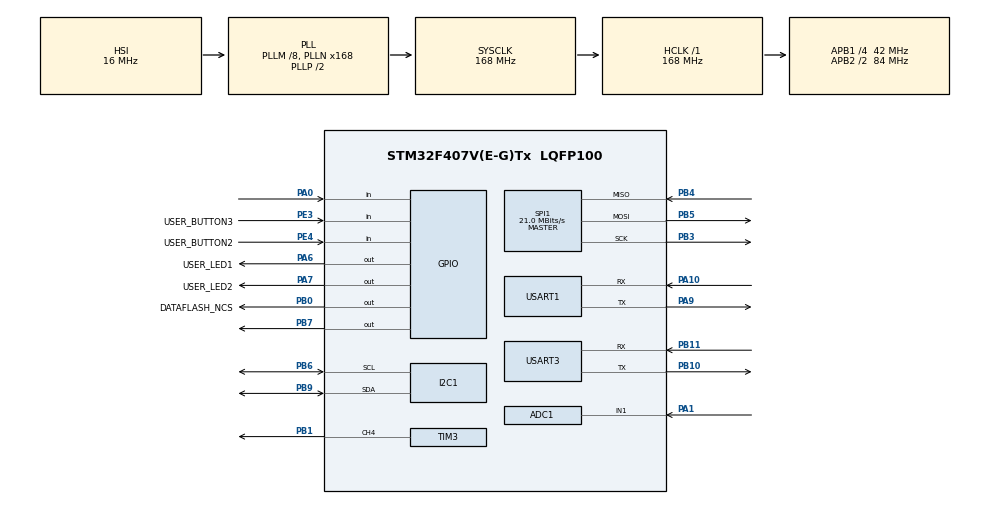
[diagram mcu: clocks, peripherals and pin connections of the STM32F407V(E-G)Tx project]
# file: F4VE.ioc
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ADC1.Channel-0\#ChannelRegularConversion=ADC_CHANNEL_1
ADC1.NbrOfConversionFlag=1
ADC1.Rank-0\#ChannelRegularConversion=1
ADC1.SamplingTime-0\#ChannelRegularConversion=ADC_SAMPLETIME_3CYCLES
ADC1.master=1
Mcu.Family=STM32F4
Mcu.Name=STM32F407V(E-G)Tx
Mcu.Package=LQFP100
NVIC.PriorityGroup=NVIC_PRIORITYGROUP_4
NVIC.SPI1_IRQn=true\:0\:0\:false\:false\:true\:true\:true\:true
PA0-WKUP.Signal=GPIO_Input
PA1.Signal=ADCx_IN1
PA10.Mode=Asynchronous
PA10.Signal=USART1_RX
PA6.GPIO_Label=USER_LED1
PA6.Signal=GPIO_Output
PA7.GPIO_Label=USER_LED2
PA7.Signal=GPIO_Output
PA9.Mode=Asynchronous
PA9.Signal=USART1_TX
PB0.GPIO_Label=DATAFLASH_NCS
PB0.Signal=GPIO_Output
PB1.Signal=S_TIM3_CH4
PB10.Mode=Asynchronous
PB10.Signal=USART3_TX
PB11.Mode=Asynchronous
PB11.Signal=USART3_RX
PB3.GPIO_Speed=GPIO_SPEED_FREQ_LOW
PB3.Mode=Full_Duplex_Master
PB3.Signal=SPI1_SCK
PB4.GPIO_Speed=GPIO_SPEED_FREQ_LOW
PB4.Mode=Full_Duplex_Master
PB4.Signal=SPI1_MISO
PB5.GPIO_Speed=GPIO_SPEED_FREQ_LOW
PB5.Mode=Full_Duplex_Master
PB5.Signal=SPI1_MOSI
PB6.Mode=I2C
PB6.Signal=I2C1_SCL
PB7.Signal=GPIO_Output
PB9.Mode=I2C
PB9.Signal=I2C1_SDA
PE3.GPIO_Label=USER_BUTTON3
PE3.GPIO_PuPd=GPIO_PULLUP
PE3.Signal=GPIO_Input
PE4.GPIO_Label=USER_BUTTON2
PE4.GPIO_PuPd=GPIO_PULLUP
PE4.Signal=GPIO_Input
ProjectManager.HeapSize=0x200
ProjectManager.StackSize=0x400
ProjectManager.TargetToolchain=STM32CubeIDE
RCC.48MHZClocksFreq_Value=84000000
RCC.AHBFreq_Value=168000000
RCC.APB1CLKDivider=RCC_HCLK_DIV4
RCC.APB1Freq_Value=42000000
RCC.APB1TimFreq_Value=84000000
RCC.APB2CLKDivider=RCC_HCLK_DIV2
RCC.APB2Freq_Value=84000000
RCC.APB2TimFreq_Value=168000000
RCC.CortexFreq_Value=168000000
RCC.HCLKFreq_Value=168000000
RCC.HSE_VALUE=25000000
RCC.HSI_VALUE=16000000
RCC.LSE_VALUE=32768
RCC.PLLM=8
RCC.PLLN=168
RCC.SYSCLKFreq_VALUE=168000000
RCC.SYSCLKSource=RCC_SYSCLKSOURCE_PLLCLK
RCC.VCOOutputFreq_Value=336000000
SH.ADCx_IN1.0=ADC1_IN1,IN1
SH.S_TIM3_CH4.0=TIM3_CH4,PWM Generation4 CH4
SPI1.BaudRatePrescaler=SPI_BAUDRATEPRESCALER_4
SPI1.CalculateBaudRate=21.0 MBits/s
SPI1.Direction=SPI_DIRECTION_2LINES
SPI1.Mode=SPI_MODE_MASTER
SPI1.VirtualType=VM_MASTER
TIM3.Channel-PWM\ Generation4\ CH4=TIM_CHANNEL_4
USART1.VirtualMode=VM_ASYNC
USART3.VirtualMode=VM_ASYNC
VP_RTC_VS_RTC_Activate.Mode=RTC_Enabled
VP_RTC_VS_RTC_Calendar.Mode=RTC_Calendar
board=custom

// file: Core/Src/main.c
/* USER CODE BEGIN Header */
/**
  ******************************************************************************
  * @file           : main.c
  * @brief          : Main program body
  ******************************************************************************
  * @attention
  *
  * Copyright (c) 2024 STMicroelectronics.
  * All rights reserved.
  *
  * This software is licensed under terms that can be found in the LICENSE file
  * in the root directory of this software component.
  * If no LICENSE file comes with this software, it is provided AS-IS.
  *
  ******************************************************************************
  */
/* USER CODE END Header */
#include "main.h"

ADC_HandleTypeDef hadc1;

I2C_HandleTypeDef hi2c1;

RTC_HandleTypeDef hrtc;

SPI_HandleTypeDef hspi1;

TIM_HandleTypeDef htim3;

UART_HandleTypeDef huart1;
UART_HandleTypeDef huart3;

void SystemClock_Config(void);
static void MX_GPIO_Init(void);
static void MX_SPI1_Init(void);
static void MX_USART1_UART_Init(void);
static void MX_RTC_Init(void);
static void MX_USART3_UART_Init(void);
static void MX_TIM3_Init(void);
static void MX_ADC1_Init(void);
static void MX_I2C1_Init(void);

int main(void)
{

  /* MCU Configuration--------------------------------------------------------*/

  /* Reset of all peripherals, Initializes the Flash interface and the Systick. */
  HAL_Init();

  /* Configure the system clock */
  SystemClock_Config();

  /* Initialize all configured peripherals */
  MX_GPIO_Init();
  MX_SPI1_Init();
  MX_USART1_UART_Init();
  MX_RTC_Init();
  MX_USART3_UART_Init();
  MX_TIM3_Init();
  MX_ADC1_Init();
  MX_I2C1_Init();
  /* USER CODE BEGIN 2 */
  app();
  /* USER CODE END 2 */

  /* Infinite loop */
  while (1)
  {

  }
}

void SystemClock_Config(void)
{
  RCC_OscInitTypeDef RCC_OscInitStruct = {0};
  RCC_ClkInitTypeDef RCC_ClkInitStruct = {0};

  /** Configure the main internal regulator output voltage
  */
  __HAL_RCC_PWR_CLK_ENABLE();
  __HAL_PWR_VOLTAGESCALING_CONFIG(PWR_REGULATOR_VOLTAGE_SCALE1);

  /** Initializes the RCC Oscillators according to the specified parameters
  * in the RCC_OscInitTypeDef structure.
  */
  RCC_OscInitStruct.OscillatorType = RCC_OSCILLATORTYPE_HSI|RCC_OSCILLATORTYPE_LSI;
  RCC_OscInitStruct.HSIState = RCC_HSI_ON;
  RCC_OscInitStruct.HSICalibrationValue = RCC_HSICALIBRATION_DEFAULT;
  RCC_OscInitStruct.LSIState = RCC_LSI_ON;
  RCC_OscInitStruct.PLL.PLLState = RCC_PLL_ON;
  RCC_OscInitStruct.PLL.PLLSource = RCC_PLLSOURCE_HSI;
  RCC_OscInitStruct.PLL.PLLM = 8;
  RCC_OscInitStruct.PLL.PLLN = 168;
  RCC_OscInitStruct.PLL.PLLP = RCC_PLLP_DIV2;
  RCC_OscInitStruct.PLL.PLLQ = 4;
  if (HAL_RCC_OscConfig(&RCC_OscInitStruct) != HAL_OK)
  {
    Error_Handler();
  }

  /** Initializes the CPU, AHB and APB buses clocks
  */
  RCC_ClkInitStruct.ClockType = RCC_CLOCKTYPE_HCLK|RCC_CLOCKTYPE_SYSCLK
                              |RCC_CLOCKTYPE_PCLK1|RCC_CLOCKTYPE_PCLK2;
  RCC_ClkInitStruct.SYSCLKSource = RCC_SYSCLKSOURCE_PLLCLK;
  RCC_ClkInitStruct.AHBCLKDivider = RCC_SYSCLK_DIV1;
  RCC_ClkInitStruct.APB1CLKDivider = RCC_HCLK_DIV4;
  RCC_ClkInitStruct.APB2CLKDivider = RCC_HCLK_DIV2;

  if (HAL_RCC_ClockConfig(&RCC_ClkInitStruct, FLASH_LATENCY_5) != HAL_OK)
  {
    Error_Handler();
  }
}

static void MX_ADC1_Init(void)
{

  ADC_ChannelConfTypeDef sConfig = {0};

  /** Configure the global features of the ADC (Clock, Resolution, Data Alignment and number of conversion)
  */
  hadc1.Instance = ADC1;
  hadc1.Init.ClockPrescaler = ADC_CLOCK_SYNC_PCLK_DIV4;
  hadc1.Init.Resolution = ADC_RESOLUTION_12B;
  hadc1.Init.ScanConvMode = DISABLE;
  hadc1.Init.ContinuousConvMode = DISABLE;
  hadc1.Init.DiscontinuousConvMode = DISABLE;
  hadc1.Init.ExternalTrigConvEdge = ADC_EXTERNALTRIGCONVEDGE_NONE;
  hadc1.Init.ExternalTrigConv = ADC_SOFTWARE_START;
  hadc1.Init.DataAlign = ADC_DATAALIGN_RIGHT;
  hadc1.Init.NbrOfConversion = 1;
  hadc1.Init.DMAContinuousRequests = DISABLE;
  hadc1.Init.EOCSelection = ADC_EOC_SINGLE_CONV;
  if (HAL_ADC_Init(&hadc1) != HAL_OK)
  {
    Error_Handler();
  }

  /** Configure for the selected ADC regular channel its corresponding rank in the sequencer and its sample time.
  */
  sConfig.Channel = ADC_CHANNEL_1;
  sConfig.Rank = 1;
  sConfig.SamplingTime = ADC_SAMPLETIME_3CYCLES;
  if (HAL_ADC_ConfigChannel(&hadc1, &sConfig) != HAL_OK)
  {
    Error_Handler();
  }

}

static void MX_I2C1_Init(void)
{

  hi2c1.Instance = I2C1;
  hi2c1.Init.ClockSpeed = 100000;
  hi2c1.Init.DutyCycle = I2C_DUTYCYCLE_2;
  hi2c1.Init.OwnAddress1 = 0;
  hi2c1.Init.AddressingMode = I2C_ADDRESSINGMODE_7BIT;
  hi2c1.Init.DualAddressMode = I2C_DUALADDRESS_DISABLE;
  hi2c1.Init.OwnAddress2 = 0;
  hi2c1.Init.GeneralCallMode = I2C_GENERALCALL_DISABLE;
  hi2c1.Init.NoStretchMode = I2C_NOSTRETCH_DISABLE;
  if (HAL_I2C_Init(&hi2c1) != HAL_OK)
  {
    Error_Handler();
  }

}

static void MX_RTC_Init(void)
{

  RTC_TimeTypeDef sTime = {0};
  RTC_DateTypeDef sDate = {0};

  /** Initialize RTC Only
  */
  hrtc.Instance = RTC;
  hrtc.Init.HourFormat = RTC_HOURFORMAT_24;
  hrtc.Init.AsynchPrediv = 127;
  hrtc.Init.SynchPrediv = 255;
  hrtc.Init.OutPut = RTC_OUTPUT_DISABLE;
  hrtc.Init.OutPutPolarity = RTC_OUTPUT_POLARITY_HIGH;
  hrtc.Init.OutPutType = RTC_OUTPUT_TYPE_OPENDRAIN;
  if (HAL_RTC_Init(&hrtc) != HAL_OK)
  {
    Error_Handler();
  }

  /** Initialize RTC and set the Time and Date
  */
  sTime.Hours = 0x0;
  sTime.Minutes = 0x0;
  sTime.Seconds = 0x0;
  sTime.DayLightSaving = RTC_DAYLIGHTSAVING_NONE;
  sTime.StoreOperation = RTC_STOREOPERATION_RESET;
  if (HAL_RTC_SetTime(&hrtc, &sTime, RTC_FORMAT_BCD) != HAL_OK)
  {
    Error_Handler();
  }
  sDate.WeekDay = RTC_WEEKDAY_MONDAY;
  sDate.Month = RTC_MONTH_JANUARY;
  sDate.Date = 0x1;
  sDate.Year = 0x0;

  if (HAL_RTC_SetDate(&hrtc, &sDate, RTC_FORMAT_BCD) != HAL_OK)
  {
    Error_Handler();
  }

}

static void MX_SPI1_Init(void)
{

  /* SPI1 parameter configuration*/
  hspi1.Instance = SPI1;
  hspi1.Init.Mode = SPI_MODE_MASTER;
  hspi1.Init.Direction = SPI_DIRECTION_2LINES;
  hspi1.Init.DataSize = SPI_DATASIZE_8BIT;
  hspi1.Init.CLKPolarity = SPI_POLARITY_LOW;
  hspi1.Init.CLKPhase = SPI_PHASE_1EDGE;
  hspi1.Init.NSS = SPI_NSS_SOFT;
  hspi1.Init.BaudRatePrescaler = SPI_BAUDRATEPRESCALER_4;
  hspi1.Init.FirstBit = SPI_FIRSTBIT_MSB;
  hspi1.Init.TIMode = SPI_TIMODE_DISABLE;
  hspi1.Init.CRCCalculation = SPI_CRCCALCULATION_DISABLE;
  hspi1.Init.CRCPolynomial = 10;
  if (HAL_SPI_Init(&hspi1) != HAL_OK)
  {
    Error_Handler();
  }

}

static void MX_TIM3_Init(void)
{

  TIM_MasterConfigTypeDef sMasterConfig = {0};
  TIM_OC_InitTypeDef sConfigOC = {0};

  htim3.Instance = TIM3;
  htim3.Init.Prescaler = 0;
  htim3.Init.CounterMode = TIM_COUNTERMODE_UP;
  htim3.Init.Period = 65535;
  htim3.Init.ClockDivision = TIM_CLOCKDIVISION_DIV1;
  htim3.Init.AutoReloadPreload = TIM_AUTORELOAD_PRELOAD_DISABLE;
  if (HAL_TIM_PWM_Init(&htim3) != HAL_OK)
  {
    Error_Handler();
  }
  sMasterConfig.MasterOutputTrigger = TIM_TRGO_RESET;
  sMasterConfig.MasterSlaveMode = TIM_MASTERSLAVEMODE_DISABLE;
  if (HAL_TIMEx_MasterConfigSynchronization(&htim3, &sMasterConfig) != HAL_OK)
  {
    Error_Handler();
  }
  sConfigOC.OCMode = TIM_OCMODE_PWM1;
  sConfigOC.Pulse = 0;
  sConfigOC.OCPolarity = TIM_OCPOLARITY_HIGH;
  sConfigOC.OCFastMode = TIM_OCFAST_DISABLE;
  if (HAL_TIM_PWM_ConfigChannel(&htim3, &sConfigOC, TIM_CHANNEL_4) != HAL_OK)
  {
    Error_Handler();
  }
  HAL_TIM_MspPostInit(&htim3);

}

static void MX_USART1_UART_Init(void)
{

  huart1.Instance = USART1;
  huart1.Init.BaudRate = 115200;
  huart1.Init.WordLength = UART_WORDLENGTH_8B;
  huart1.Init.StopBits = UART_STOPBITS_1;
  huart1.Init.Parity = UART_PARITY_NONE;
  huart1.Init.Mode = UART_MODE_TX_RX;
  huart1.Init.HwFlowCtl = UART_HWCONTROL_NONE;
  huart1.Init.OverSampling = UART_OVERSAMPLING_16;
  if (HAL_UART_Init(&huart1) != HAL_OK)
  {
    Error_Handler();
  }

}

static void MX_USART3_UART_Init(void)
{

  huart3.Instance = USART3;
  huart3.Init.BaudRate = 115200;
  huart3.Init.WordLength = UART_WORDLENGTH_8B;
  huart3.Init.StopBits = UART_STOPBITS_1;
  huart3.Init.Parity = UART_PARITY_NONE;
  huart3.Init.Mode = UART_MODE_TX_RX;
  huart3.Init.HwFlowCtl = UART_HWCONTROL_NONE;
  huart3.Init.OverSampling = UART_OVERSAMPLING_16;
  if (HAL_UART_Init(&huart3) != HAL_OK)
  {
    Error_Handler();
  }

}

static void MX_GPIO_Init(void)
{
  GPIO_InitTypeDef GPIO_InitStruct = {0};

  /* GPIO Ports Clock Enable */
  __HAL_RCC_GPIOE_CLK_ENABLE();
  __HAL_RCC_GPIOA_CLK_ENABLE();
  __HAL_RCC_GPIOB_CLK_ENABLE();

  /*Configure GPIO pin Output Level */
  HAL_GPIO_WritePin(GPIOA, USER_LED1_Pin|USER_LED2_Pin, GPIO_PIN_RESET);

  /*Configure GPIO pin Output Level */
  HAL_GPIO_WritePin(GPIOB, DATAFLASH_NCS_Pin|GPIO_PIN_7, GPIO_PIN_RESET);

  /*Configure GPIO pins : USER_BUTTON3_Pin USER_BUTTON2_Pin */
  GPIO_InitStruct.Pin = USER_BUTTON3_Pin|USER_BUTTON2_Pin;
  GPIO_InitStruct.Mode = GPIO_MODE_INPUT;
  GPIO_InitStruct.Pull = GPIO_PULLUP;
  HAL_GPIO_Init(GPIOE, &GPIO_InitStruct);

  /*Configure GPIO pin : PA0 */
  GPIO_InitStruct.Pin = GPIO_PIN_0;
  GPIO_InitStruct.Mode = GPIO_MODE_INPUT;
  GPIO_InitStruct.Pull = GPIO_NOPULL;
  HAL_GPIO_Init(GPIOA, &GPIO_InitStruct);

  /*Configure GPIO pins : USER_LED1_Pin USER_LED2_Pin */
  GPIO_InitStruct.Pin = USER_LED1_Pin|USER_LED2_Pin;
  GPIO_InitStruct.Mode = GPIO_MODE_OUTPUT_PP;
  GPIO_InitStruct.Pull = GPIO_NOPULL;
  GPIO_InitStruct.Speed = GPIO_SPEED_FREQ_LOW;
  HAL_GPIO_Init(GPIOA, &GPIO_InitStruct);

  /*Configure GPIO pins : DATAFLASH_NCS_Pin PB7 */
  GPIO_InitStruct.Pin = DATAFLASH_NCS_Pin|GPIO_PIN_7;
  GPIO_InitStruct.Mode = GPIO_MODE_OUTPUT_PP;
  GPIO_InitStruct.Pull = GPIO_NOPULL;
  GPIO_InitStruct.Speed = GPIO_SPEED_FREQ_LOW;
  HAL_GPIO_Init(GPIOB, &GPIO_InitStruct);

}

void Error_Handler(void)
{
  __disable_irq();
  while (1)
  {
  }
}
